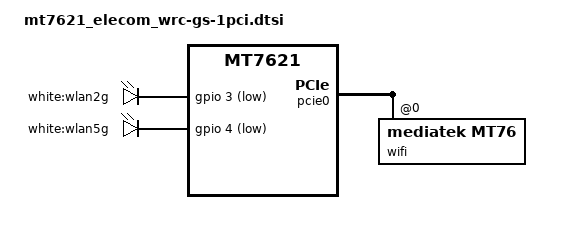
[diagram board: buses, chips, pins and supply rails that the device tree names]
// SPDX-License-Identifier: GPL-2.0-only

#include "mt7621_elecom_wrc-gs.dtsi"

&leds {
	wlan2g {
		label = "white:wlan2g";
		gpios = <&gpio 3 GPIO_ACTIVE_LOW>;
	};

	wlan5g {
		label = "white:wlan5g";
		gpios = <&gpio 4 GPIO_ACTIVE_LOW>;
	};
};

&state_default {
	gpio {
		groups = "i2c", "uart3", "jtag", "wdt", "sdhci";
		function = "gpio";
	};
};

&pcie0 {
	wifi: wifi@0,0 {
		compatible = "mediatek,mt76";
		reg = <0x0000 0 0 0 0>;
		mediatek,mtd-eeprom = <&factory 0x0>;
	};
};
